# nrf7120E_enga_application register map
Vendor: Nordic Semiconductor; Series: nrf71; File version: 1
CPU: CM33 r0p4, little endian, MPU, FPU, 3 interrupt priority bits, 270 interrupts, 4 SAU regions
Registers are 32-bit, read-write, reset 0x0 unless marked. A register's access mark holds for its fields unless they carry their own. Offsets are from the block's base; [hi:lo] are bit positions; lines under a group give offsets from that group; {n}, {i} and the like mark numbered series; 'fields as' and 'values as' point back to an identical list.

## GLOBAL_USBHSCORE_NS (part 3 of 3) — USBHSCORE 0
Base 0x40020000
Same registers: GLOBAL_USBHSCORE_S 0x50020000
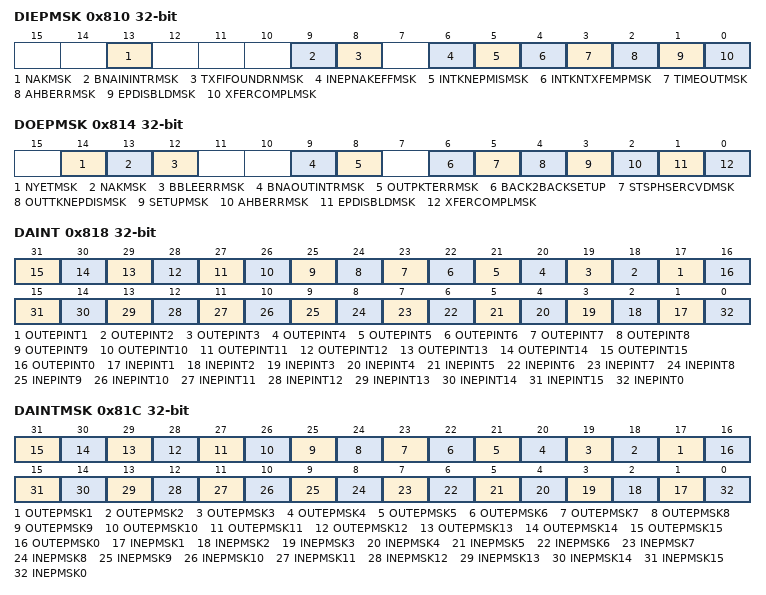
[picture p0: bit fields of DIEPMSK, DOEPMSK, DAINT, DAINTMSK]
0x810 DIEPMSK — Device IN Endpoint Common Interrupt Mask Register
  [13] NAKMSK — NAK interrupt Mask (NAKMsk)
    0=MASK (Mask NAK Interrupt); 1=NOMASK (No Mask NAK Interrupt)
  [9] BNAININTRMSK — BNA interrupt Mask (BNAInIntrMsk)
    0=MASK (Mask BNA Interrupt); 1=NOMASK (No BNA Interrupt Mask)
  [8] TXFIFOUNDRNMSK — Fifo Underrun Mask (TxfifoUndrnMsk)
    0=MASK (Mask Fifo Underrun Interrupt); 1=NOMASK (No Fifo Underrun Interrupt Mask)
  [6] INEPNAKEFFMSK — IN Endpoint NAK Effective Mask (INEPNakEffMsk)
    0=MASK (Mask IN Endpoint NAK Effective Interrupt); 1=NOMASK (No IN Endpoint NAK Effective Interrupt Mask)
  [5] INTKNEPMISMSK — IN Token received with EP Mismatch Mask (INTknEPMisMsk)
    0=MASK (Mask IN Token received with EP Mismatch Interrupt); 1=NOMASK (No Mask IN Token received with EP Mismatch Interrupt)
  [4] INTKNTXFEMPMSK — IN Token Received When TxFIFO Empty Mask (INTknTXFEmpMsk)
    0=MASK (Mask IN Token Received When TxFIFO Empty Interrupt); 1=NOMASK (No IN Token Received When TxFIFO Empty Interrupt)
  [3] TIMEOUTMSK — Timeout Condition Mask (TimeOUTMsk) (Non-isochronous endpoints)
    0=MASK (Mask Timeout Condition Interrupt); 1=NOMASK (No Timeout Condition Interrupt Mask)
  [2] AHBERRMSK — AHB Error Mask (AHBErrMsk)
    0=MASK (Mask AHB Error Interrupt); 1=NOMASK (No AHB Error Interrupt Mask)
  [1] EPDISBLDMSK — Endpoint Disabled Interrupt Mask (EPDisbldMsk)
    0=MASK (Mask Endpoint Disabled Interrupt); 1=NOMASK (No Endpoint Disabled Interrupt Mask)
  [0] XFERCOMPLMSK — Transfer Completed Interrupt Mask (XferComplMsk)
    0=MASK (Mask Transfer Completed Interrupt); 1=NOMASK (No Transfer Completed Interrupt Mask)
0x814 DOEPMSK — Device OUT Endpoint Common Interrupt Mask Register
  [14] NYETMSK — NYET interrupt Mask (NYETMsk)
    0=MASK (Mask NYET Interrupt); 1=NOMASK (No NYET Interrupt Mask)
  [13] NAKMSK — NAK interrupt Mask (NAKMsk)
    0=MASK (Mask NAK Interrupt); 1=NOMASK (No NAK Interrupt Mask)
  [12] BBLEERRMSK — Babble Error interrupt Mask (BbleErrMsk)
    0=MASK (Mask Babble Error Interrupt); 1=NOMASK (No Babble Error Interrupt Mask)
  [9] BNAOUTINTRMSK — BNA interrupt Mask (BnaOutIntrMsk)
    values as DIEPMSK.BNAININTRMSK
  [8] OUTPKTERRMSK — OUT Packet Error Mask (OutPktErrMsk)
    0=MASK (Mask OUT Packet Error Interrupt); 1=NOMASK (No OUT Packet Error Interrupt Mask)
  [6] BACK2BACKSETUP — Back-to-Back SETUP Packets Received Mask (Back2BackSETup)
    0=MASK (Mask Back-to-Back SETUP Packets Received Interrupt); 1=NOMASK (No Back-to-Back SETUP Packets Received Interrupt Mask)
  [5] STSPHSERCVDMSK — Status Phase Received Mask (StsPhseRcvdMsk)
    0=MASK (Status Phase Received Mask); 1=NOMASK (No Status Phase Received Mask)
  [4] OUTTKNEPDISMSK — OUT Token Received when Endpoint Disabled Mask (OUTTknEPdisMsk)
    0=MASK (Mask OUT Token Received when Endpoint Disabled Interrupt); 1=NOMASK (No OUT Token Received when Endpoint Disabled Interrupt Mask)
  [3] SETUPMSK — SETUP Phase Done Mask (SetUPMsk)
    0=MASK (Mask SETUP Phase Done Interrupt); 1=NOMASK (No SETUP Phase Done Interrupt Mask)
  [2] AHBERRMSK — AHB Error (AHBErrMsk)
    values as DIEPMSK.AHBERRMSK
  [1] EPDISBLDMSK — Endpoint Disabled Interrupt Mask (EPDisbldMsk)
    values as DIEPMSK.EPDISBLDMSK
  [0] XFERCOMPLMSK — Transfer Completed Interrupt Mask (XferComplMsk)
    values as DIEPMSK.XFERCOMPLMSK
0x818 DAINT — Device All Endpoints Interrupt Register
  [n+16] OUTEPINT{n} ro (n=1..15) — OUT Endpoint {n} Interrupt Bit
    0=INACTIVE (No Interrupt); 1=ACTIVE (Interrupt is active for the OUT EP)
  [16] OUTEPINT0 ro — OUT Endpoint 0 Interrupt Bit
    0=INACTIVE (No Interrupt); 1=ACTIVE (Interrupt is active for OUT EP0)
  [n] INEPINT{n} ro (n=1..15) — IN Endpoint {n} Interrupt Bit
    0=INACTIVE (No Interrupt); 1=ACTIVE (Interrupt is active for the IN EP)
  [0] INEPINT0 ro — IN Endpoint 0 Interrupt Bit
    0=INACTIVE (No Interrupt); 1=ACTIVE (Interrupt is active for IN EP0)
0x81C DAINTMSK — Device All Endpoints Interrupt Mask Register
  [n+16] OUTEPMSK{n} (n=1..15) — OUT Endpoint {n} Interrupt mask Bit
    0=MASK (Mask OUT Endpoint Interrupt); 1=NOMASK (No Interrupt mask)
  [16] OUTEPMSK0 — OUT Endpoint 0 Interrupt mask Bit
    0=MASK (Mask OUT Endpoint 0 Interrupt); 1=NOMASK (No Interrupt mask)
  [n] INEPMSK{n} (n=1..15) — IN Endpoint {n} Interrupt mask Bit
    0=MASK (Mask IN Endpoint Interrupt); 1=NOMASK (No Interrupt mask)
  [0] INEPMSK0 — IN Endpoint 0 Interrupt mask Bit
    0=MASK (Mask IN Endpoint 0 Interrupt); 1=NOMASK (No Interrupt mask)
0x828 DVBUSDIS reset 0x17D7 — Device VBUS Discharge Time Register
  [15:0] DVBUSDIS — Device VBUS Discharge Time (DVBUSDis)
0x82C DVBUSPULSE reset 0x5B8 — Device VBUS Pulsing Time Register
  [11:0] DVBUSPULSE — Device VBUS Pulsing Time (DVBUSPulse)
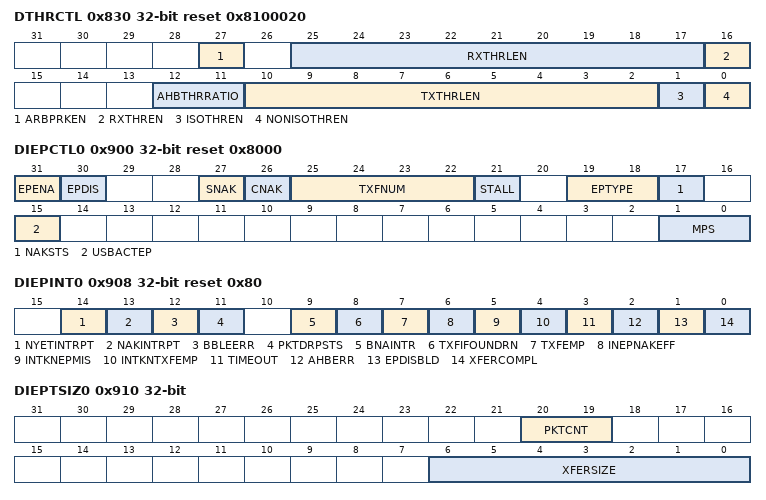
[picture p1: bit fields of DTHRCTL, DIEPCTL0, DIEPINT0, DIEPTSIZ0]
0x830 DTHRCTL reset 0x8100020 — Device Threshold Control Register
  [27] ARBPRKEN — Arbiter Parking Enable (ArbPrkEn)
    0=DISABLED (Disable DMA arbiter parking); 1=ENABLED (Enable DMA arbiter parking for IN endpoints)
  [25:17] RXTHRLEN — Receive Threshold Length (RxThrLen)
  [16] RXTHREN — Receive Threshold Enable (RxThrEn)
    0=DISABLED (Disable thresholding); 1=ENABLED (Enable thresholding in the receive direction)
  [12:11] AHBTHRRATIO — AHB Threshold Ratio (AHBThrRatio)
    0=THRESZERO (AHB threshold = MAC threshold); 1=THRESONE (AHB threshold = MAC threshold /2); 2=THRESTWO (AHB threshold = MAC threshold /4); 3=THRESTHREE (AHB threshold = MAC threshold /8)
  [10:2] TXTHRLEN — Transmit Threshold Length (TxThrLen)
  [1] ISOTHREN
    0=DISABLED (No thresholding); 1=ENABLED (Enables thresholding for isochronous IN endpoints)
  [0] NONISOTHREN — Non-ISO IN Endpoints Threshold Enable. (NonISOThrEn)
    0=DISABLED (No thresholding); 1=ENABLED (Enable thresholding for non-isochronous IN endpoints)
0x834 DIEPEMPMSK — Device IN Endpoint FIFO Empty Interrupt Mask Register
  [15:0] INEPTXFEMPMSK — IN EP Tx FIFO Empty Interrupt Mask Bits (InEpTxfEmpMsk)
    1=EP0_MASK (Mask IN EP0 Tx FIFO Empty Interrupt); 2=EP1_MASK (Mask IN EP1 Tx FIFO Empty Interrupt); 4=EP2_MASK (Mask IN EP2 Tx FIFO Empty Interrupt); 8=EP3_MASK (Mask IN EP3 Tx FIFO Empty Interrupt); 16=EP4_MASK (Mask IN EP4 Tx FIFO Empty Interrupt); 32=EP5_MASK (Mask IN EP5 Tx FIFO Empty Interrupt); 64=EP6_MASK (Mask IN EP6 Tx FIFO Empty Interrupt); 128=EP7_MASK (Mask IN EP7 Tx FIFO Empty Interrupt); 0x100=EP8_MASK (Mask IN EP8 Tx FIFO Empty Interrupt); 0x200=EP9_MASK (Mask IN EP9 Tx FIFO Empty Interrupt); 0x400=EP10_MASK (Mask IN EP10 Tx FIFO Empty Interrupt); 0x800=EP11_MASK (Mask IN EP11 Tx FIFO Empty Interrupt); 0x1000=EP12_MASK (Mask IN EP12 Tx FIFO Empty Interrupt); 0x2000=EP13_MASK (Mask IN EP13 Tx FIFO Empty Interrupt); 0x4000=EP14_MASK (Mask IN EP14 Tx FIFO Empty Interrupt); 0x8000=EP15_MASK (Mask IN EP15 Tx FIFO Empty Interrupt)
0x900 DIEPCTL0 reset 0x8000 — Device Control IN Endpoint 0 Control Register
  [31] EPENA — Endpoint Enable (EPEna)
    0=INACTIVE (No action); 1=ACTIVE (Enable Endpoint)
  [30] EPDIS — Endpoint Disable (EPDis)
    0=INACTIVE (No action); 1=ACTIVE (Disabled Endpoint)
  [27] SNAK wo
    0=NOSET (No action); 1=SET (Set NAK)
  [26] CNAK wo
    0=NOCLEAR (No action); 1=CLEAR (Clear NAK)
  [25:22] TXFNUM — TxFIFO Number (TxFNum)
    {v}=TXFIFO{v} (v=0..15)
  [21] STALL — STALL Handshake (Stall)
    0=INACTIVE (No Stall); 1=ACTIVE (Stall Handshake)
  [19:18] EPTYPE ro — Endpoint Type (EPType)
    0=ACTIVE (Endpoint Control 0)
  [17] NAKSTS ro — NAK Status (NAKSts)
    0=INACTIVE (The core is transmitting non-NAK handshakes based on the FIFO status); 1=ACTIVE (The core is transmitting NAK handshakes on this endpoint)
  [15] USBACTEP ro — USB Active Endpoint (USBActEP)
    1=ACTIVE0 (Control endpoint is always active)
  [1:0] MPS — Maximum Packet Size (MPS)
    0=BYTES64 (64 bytes); 1=BYTES32 (32 bytes); 2=BYTES16 (16 bytes); 3=BYTES8 (8 bytes)
0x908 DIEPINT0 reset 0x80 — Device IN Endpoint 0 Interrupt Register
  [14] NYETINTRPT — NYET Interrupt (NYETIntrpt)
    0=INACTIVE (No interrupt); 1=ACTIVE (NYET Interrupt)
  [13] NAKINTRPT — NAK Interrupt (NAKInterrupt)
    0=INACTIVE (No interrupt); 1=ACTIVE (NAK Interrupt)
  [12] BBLEERR — NAK Interrupt (BbleErr)
    0=INACTIVE (No interrupt); 1=ACTIVE (BbleErr interrupt)
  [11] PKTDRPSTS — Packet Drop Status (PktDrpSts)
    0=INACTIVE (No interrupt); 1=ACTIVE (Packet Drop Status)
  [9] BNAINTR — BNA (Buffer Not Available) Interrupt (BNAIntr)
    0=INACTIVE (No BNA interrupt); 1=ACTIVE (BNA interrupt)
  [8] TXFIFOUNDRN — Fifo Underrun (TxfifoUndrn)
    0=INACTIVE (No Fifo Underrun interrupt); 1=ACTIVE (Fifo Underrun interrupt)
  [7] TXFEMP ro — Transmit FIFO Empty (TxFEmp)
    0=INACTIVE (No Transmit FIFO Empty interrupt); 1=ACTIVE (Transmit FIFO Empty interrupt)
  [6] INEPNAKEFF — IN Endpoint NAK Effective (INEPNakEff)
    0=INACTIVE (No IN Endpoint NAK Effective interrupt); 1=ACTIVE (IN Endpoint NAK Effective interrupt)
  [5] INTKNEPMIS — IN Token Received with EP Mismatch (INTknEPMis)
    0=INACTIVE (No IN Token Received with EP Mismatch interrupt); 1=ACTIVE (IN Token Received with EP Mismatch interrupt)
  [4] INTKNTXFEMP — IN Token Received When TxFIFO is Empty (INTknTXFEmp)
    0=INACTIVE (No IN Token Received when TxFIFO Empty interrupt); 1=ACTIVE (IN Token Received when TxFIFO Empty Interrupt)
  [3] TIMEOUT — Timeout Condition (TimeOUT)
    0=INACTIVE (No Timeout interrupt); 1=ACTIVE (Timeout interrupt)
  [2] AHBERR — AHB Error (AHBErr)
    0=INACTIVE (No AHB Error Interrupt); 1=ACTIVE (AHB Error interrupt)
  [1] EPDISBLD — Endpoint Disabled Interrupt (EPDisbld)
    0=INACTIVE (No Endpoint Disabled Interrupt); 1=ACTIVE (Endpoint Disabled Interrupt)
  [0] XFERCOMPL — Transfer Completed Interrupt (XferCompl)
    0=INACTIVE (No Transfer Complete Interrupt); 1=ACTIVE (Transfer Completed Interrupt)
0x910 DIEPTSIZ0 — Device IN Endpoint 0 Transfer Size Register
  [20:19] PKTCNT — Packet Count (PktCnt)
  [6:0] XFERSIZE — Transfer Size (XferSize)
0x914 DIEPDMA0 — Device IN Endpoint 0 DMA Address Register
  [31:0] DMAADDR
{0x918+0x20*i} DTXFSTS{i} reset 0xC00 (i=0..15) — Device IN Endpoint Transmit FIFO Status Register {i}
  [15:0] INEPTXFSPCAVAIL ro — IN Endpoint TxFIFO Space Avail (INEPTxFSpcAvail)
0x91C DIEPDMAB0 — Device IN Endpoint 0 Buffer Address Register
  [31:0] DMABUFFERADDR ro — Holds the current buffer address.This register is updated as and when the data
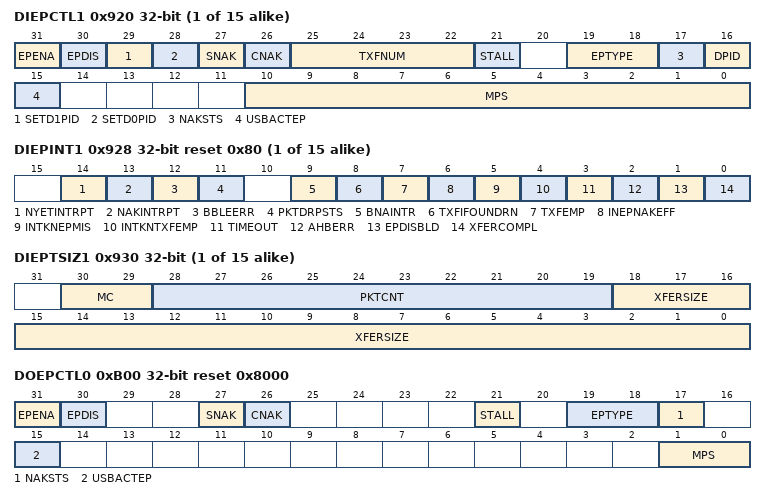
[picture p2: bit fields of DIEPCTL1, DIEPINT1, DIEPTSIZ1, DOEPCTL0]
{0x900+0x20*i} DIEPCTL{i} (i=1..15) — Device Control IN Endpoint Control Register {i}
  [31] EPENA — Endpoint Enable (EPEna)
    0=INACTIVE (No Action); 1=ACTIVE (Enable Endpoint)
  [30] EPDIS — Endpoint Disable (EPDis)
    0=INACTIVE (No Action); 1=ACTIVE (Disable Endpoint)
  [29] SETD1PID wo — Set DATA1 PID (SetD1PID)
    0=DISABLED (Disables Set DATA1 PID or Do not force Odd (micro)Frame); 1=ENABLED (Set Endpoint Data PID to DATA1 or Sets EO_FrNum field to Odd (micro)Frame)
  [28] SETD0PID wo — Set DATA0 PID (SetD0PID)
    0=DISABLED (Disables Set DATA0 PID or Do not force Even (micro)Frame); 1=ENABLED (Set Endpoint Data PID to DATA0 or Sets EO_FrNum field to Even (micro)Frame)
  [27] SNAK wo — Set NAK (SNAK)
    0=INACTIVE (No Set NAK); 1=ACTIVE (Set NAK)
  [26] CNAK wo — Clear NAK (CNAK)
    0=INACTIVE (No Clear NAK); 1=ACTIVE (Clear NAK)
  [25:22] TXFNUM — TxFIFO Number (TxFNum)
    {v}=TXFIFO{v} (v=0..15)
  [21] STALL — STALL Handshake (Stall)
    0=INACTIVE (STALL All non-active tokens); 1=ACTIVE (STALL All Active Tokens)
  [19:18] EPTYPE — Endpoint Type (EPType)
    0=CONTROL; 1=ISOCHRONOUS; 2=BULK; 3=INTERRUP (Interrupt)
  [17] NAKSTS ro — NAK Status (NAKSts)
    0=NONNAK (The core is transmitting non-NAK handshakes based on the FIFO status); 1=NAK (The core is transmitting NAK handshakes on this endpoint)
  [16] DPID ro
    0=DATA0EVENFRM (DATA0 or Even Frame); 1=DATA1ODDFRM (DATA1 or Odd Frame)
  [15] USBACTEP — USB Active Endpoint (USBActEP)
    0=DISABLED (Not Active); 1=ENABLED (USB Active Endpoint)
  [10:0] MPS — Maximum Packet Size (MPS)
{0x908+0x20*i} DIEPINT{i} reset 0x80 (i=1..15) — Device IN Endpoint Interrupt Register {i}
  [14] NYETINTRPT — NYET Interrupt (NYETIntrpt)
    0=INACTIVE (No NYET interrupt); 1=ACTIVE (NYET Interrupt)
  [13] NAKINTRPT — NAK Interrupt (NAKInterrupt)
    0=INACTIVE (No NAK interrupt); 1=ACTIVE (NAK Interrupt)
  [12] BBLEERR — NAK Interrupt (BbleErr)
    0=INACTIVE (No interrupt); 1=ACTIVE (BbleErr interrupt)
  [11] PKTDRPSTS — Packet Drop Status (PktDrpSts)
    0=INACTIVE (No interrupt); 1=ACTIVE (Packet Drop Status interrupt)
  [9] BNAINTR — BNA (Buffer Not Available) Interrupt (BNAIntr)
    0=INACTIVE (No BNA interrupt); 1=ACTIVE (BNA interrupt)
  [8] TXFIFOUNDRN — Fifo Underrun (TxfifoUndrn)
    0=INACTIVE (No Tx FIFO Underrun interrupt); 1=ACTIVE (TxFIFO Underrun interrupt)
  [7] TXFEMP ro — Transmit FIFO Empty (TxFEmp)
    values as DIEPINT0.TXFEMP
  [6] INEPNAKEFF — IN Endpoint NAK Effective (INEPNakEff)
    0=INACTIVE (No Endpoint NAK Effective interrupt); 1=ACTIVE (IN Endpoint NAK Effective interrupt)
  [5] INTKNEPMIS — IN Token Received with EP Mismatch (INTknEPMis)
    values as DIEPINT0.INTKNEPMIS
  [4] INTKNTXFEMP — IN Token Received When TxFIFO is Empty (INTknTXFEmp)
    0=INACTIVE (No IN Token Received interrupt); 1=ACTIVE (IN Token Received Interrupt)
  [3] TIMEOUT — Timeout Condition (TimeOUT)
    values as DIEPINT0.TIMEOUT
  [2] AHBERR — AHB Error (AHBErr)
    values as DIEPINT0.AHBERR
  [1] EPDISBLD — Endpoint Disabled Interrupt (EPDisbld)
    values as DIEPINT0.EPDISBLD
  [0] XFERCOMPL — Transfer Completed Interrupt (XferCompl)
    0=INACTIVE (No Transfer Complete Interrupt); 1=ACTIVE (Transfer Complete Interrupt)
{0x910+0x20*i} DIEPTSIZ{i} (i=1..15) — Device IN Endpoint Transfer Size Register {i}
  [30:29] MC
    1=PACKETONE (1 packet); 2=PACKETTWO (2 packets); 3=PACKETTHREE (3 packets)
  [28:19] PKTCNT — Packet Count (PktCnt)
  [18:0] XFERSIZE — Transfer Size (XferSize)
{0x914+0x20*i} DIEPDMA{i} (i=1..15) — Device IN Endpoint DMA Address Register {i}
  [31:0] DMAADDR — Holds the start address of the external memory for storing or fetching endpoint
{0x91C+0x20*i} DIEPDMAB{i} (i=1..15) — Device IN Endpoint Buffer Address Register {i}
  fields as DIEPDMAB0
0xB00 DOEPCTL0 reset 0x8000 — Device Control OUT Endpoint 0 Control Register
  [31] EPENA — Endpoint Enable (EPEna)
    0=INACTIVE (No action); 1=ACTIVE (Enable Endpoint)
  [30] EPDIS ro — Endpoint Disable (EPDis)
    0=INACTIVE (No Endpoint disable)
  [27] SNAK wo — Set NAK (SNAK)
    0=NOSET (No action); 1=SET (Set NAK)
  [26] CNAK wo — Clear NAK (CNAK)
    0=NOCLEAR (No action); 1=CLEAR (Clear NAK)
  [21] STALL — STALL Handshake (Stall)
    0=INACTIVE (No Stall); 1=ACTIVE (Stall Handshake)
  [19:18] EPTYPE ro — Endpoint Type (EPType)
    0=ACTIVE (Endpoint Control 0)
  [17] NAKSTS ro — NAK Status (NAKSts)
    values as DIEPCTL0.NAKSTS
  [15] USBACTEP ro — USB Active Endpoint (USBActEP)
    1=ACTIVE (USB Active Endpoint 0)
  [1:0] MPS ro — Maximum Packet Size (MPS)
    0=BYTE64 (64 bytes); 1=BYTE32 (32 bytes); 2=BYTE16 (16 bytes); 3=BYTE8 (8 bytes)
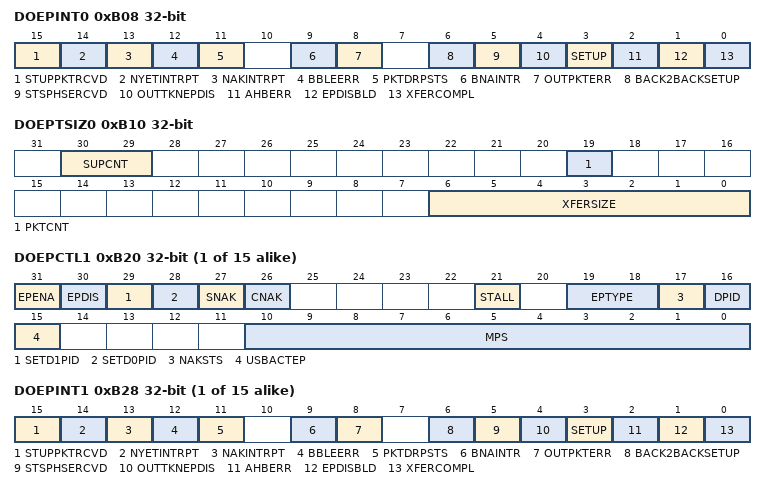
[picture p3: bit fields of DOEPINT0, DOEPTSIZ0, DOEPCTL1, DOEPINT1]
0xB08 DOEPINT0 — Device OUT Endpoint 0 Interrupt Register
  [15] STUPPKTRCVD — Setup Packet Received
    0=NOT_RCVD (No Setup packet received); 1=RCVD (Setup packet received)
  [14] NYETINTRPT — NYET Interrupt (NYETIntrpt)
    0=INACTIVE (No NYET interrupt); 1=ACTIVE (NYET Interrupt)
  [13] NAKINTRPT — NAK Interrupt (NAKInterrupt)
    0=INACTIVE (No NAK interrupt); 1=ACTIVE (NAK Interrupt)
  [12] BBLEERR — NAK Interrupt (BbleErr)
    0=INACTIVE (No BbleErr interrupt); 1=ACTIVE (BbleErr interrupt)
  [11] PKTDRPSTS — Packet Drop Status (PktDrpSts)
    values as DIEPINT1.PKTDRPSTS
  [9] BNAINTR — BNA (Buffer Not Available) Interrupt (BNAIntr)
    0=INACTIVE (No BNA interrupt); 1=ACTIVE (BNA interrupt)
  [8] OUTPKTERR — OUT Packet Error (OutPktErr)
    0=INACTIVE (No OUT Packet Error); 1=ACTIVE (OUT Packet Error)
  [6] BACK2BACKSETUP — Back-to-Back SETUP Packets Received (Back2BackSETup)
    0=INACTIVE (No Back-to-Back SETUP Packets Received); 1=ACTIVE (Back-to-Back SETUP Packets Received)
  [5] STSPHSERCVD — Status Phase Received for Control Write (StsPhseRcvd)
    0=INACTIVE (No Status Phase Received for Control Write); 1=ACTIVE (Status Phase Received for Control Write)
  [4] OUTTKNEPDIS — OUT Token Received When Endpoint Disabled (OUTTknEPdis)
    0=INACTIVE (No OUT Token Received When Endpoint Disabled); 1=ACTIVE (OUT Token Received When Endpoint Disabled)
  [3] SETUP — SETUP Phase Done (SetUp)
    0=INACTIVE (No SETUP Phase Done); 1=ACTIVE (SETUP Phase Done)
  [2] AHBERR — AHB Error (AHBErr)
    values as DIEPINT0.AHBERR
  [1] EPDISBLD — Endpoint Disabled Interrupt (EPDisbld)
    values as DIEPINT0.EPDISBLD
  [0] XFERCOMPL — Transfer Completed Interrupt (XferCompl)
    values as DIEPINT1.XFERCOMPL
0xB10 DOEPTSIZ0 — Device OUT Endpoint 0 Transfer Size Register
  [30:29] SUPCNT — SETUP Packet Count (SUPCnt)
    1=ONEPACKET (1 packet); 2=TWOPACKET (2 packets); 3=THREEPACKET (3 packets)
  [19] PKTCNT — Packet Count (PktCnt)
  [6:0] XFERSIZE — Transfer Size (XferSize)
0xB14 DOEPDMA0 — Device OUT Endpoint 0 DMA Address Register
  fields as DIEPDMA1
0xB1C DOEPDMAB0 — Device OUT Endpoint 0 DMA Buffer Address Register
  [31:0] DMABUFFERADDR ro
{0xB00+0x20*i} DOEPCTL{i} (i=1..15) — Device Control OUT Endpoint Control Register {i}
  [31] EPENA — Endpoint Enable (EPEna)
    0=INACTIVE (No Action); 1=ACTIVE (Enable Endpoint)
  [30] EPDIS — Endpoint Disable (EPDis)
    0=INACTIVE (No Action); 1=ACTIVE (Disable Endpoint)
  [29] SETD1PID wo — Set DATA1 PID (SetD1PID)
    0=DISABLED (Disables Set DATA1 PID or Do not force Odd Frame); 1=ENABLED (Set Endpoint Data PID to DATA1 or Sets EO_FrNum field to odd (micro)Frame)
  [28] SETD0PID wo — Set DATA0 PID (SetD0PID)
    0=DISABLED (Disables Set DATA0 PID or Do not force Even Frame); 1=ENABLED (Set Endpoint Data PID to DATA0 or Sets EO_FrNum field to odd (micro)Frame)
  [27] SNAK wo — Set NAK (SNAK)
    0=INACTIVE (No Set NAK); 1=ACTIVE (Set NAK)
  [26] CNAK wo
    0=INACTIVE (No Clear NAK); 1=ACTIVE (Clear NAK)
  [21] STALL — STALL Handshake (Stall)
    values as DIEPCTL1.STALL
  [19:18] EPTYPE — Endpoint Type (EPType)
    0=CONTROL; 1=ISOCHRONOUS; 2=BULK; 3=INTERRUPT
  [17] NAKSTS ro — NAK Status (NAKSts)
    values as DIEPCTL1.NAKSTS
  [16] DPID ro — Endpoint Data PID (DPID)
    0=INACTIVE (Endpoint Data PID not active); 1=ACTIVE (Endpoint Data PID active)
  [15] USBACTEP — USB Active Endpoint (USBActEP)
    0=DISABLED (Not Active); 1=ENABLED (USB Active Endpoint)
  [10:0] MPS — Maximum Packet Size (MPS)
{0xB08+0x20*i} DOEPINT{i} (i=1..15) — Device OUT Endpoint Interrupt Register {i}
  fields as DOEPINT0
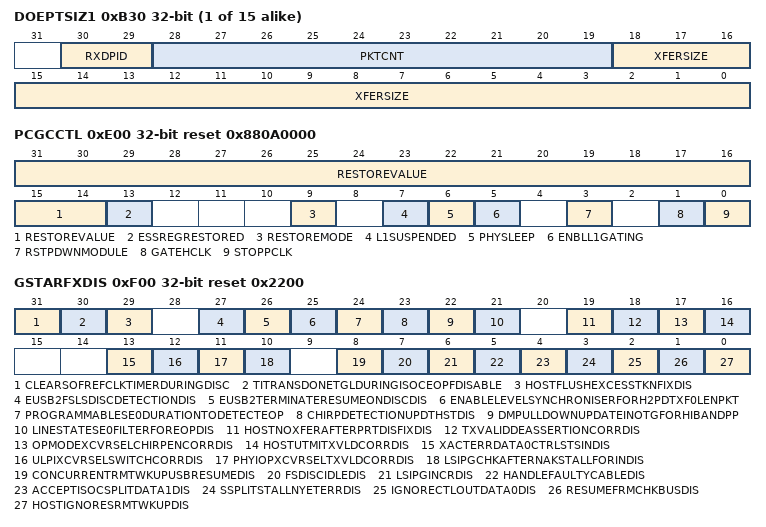
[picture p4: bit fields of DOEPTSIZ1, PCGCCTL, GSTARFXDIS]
{0xB10+0x20*i} DOEPTSIZ{i} (i=1..15) — Device OUT Endpoint Transfer Size Register {i}
  [30:29] RXDPID ro
    0=DATA0; 1=DATA2PACKET1 (DATA2 or 1 packet); 2=DATA1PACKET2 (DATA1 or 2 packets); 3=MDATAPACKET3 (MDATA or 3 packets)
  [28:19] PKTCNT — Packet Count (PktCnt)
  [18:0] XFERSIZE — Transfer Size (XferSize)
{0xB14+0x20*i} DOEPDMA{i} (i=1..15) — Device OUT Endpoint DMA Address Register {i}
  fields as DIEPDMA1
{0xB1C+0x20*i} DOEPDMAB{i} (i=1..15) — Device OUT Endpoint Buffer Address Register {i}
  fields as DIEPDMAB0
0xE00 PCGCCTL reset 0x880A0000 — Power and Clock Gating Control Register
  [31:14] RESTOREVALUE — Restore Value (RestoreValue)
  [13] ESSREGRESTORED wo — Essential Register Values Restored (EssRegRestored)
    0=NOT_RESTORED (Register values of essential registers are not restored); 1=RESTORED (Register values of essential registers have been restored)
  [9] RESTOREMODE — Restore Mode (RestoreMode)
    0=DISABLED (In Host mode,this bit indicates Host-initiated Resume and Reset. In Device mode, this bit indicates Device-initiated Remote Wakeup); 1=ENABLED (In Host mode,this bit indicates Device-initiated Remote Wakeup. In Device mode, this bit indicates Host-initiated Resume and Reset)
  [7] L1SUSPENDED ro — L1 Deep Sleep
    0=INACTIVE (Non Deep Sleep); 1=ACTIVE (Deep Sleep)
  [6] PHYSLEEP ro — PHY In Sleep
    0=INACTIVE (Phy not in Sleep state); 1=ACTIVE (Phy in Sleep state)
  [5] ENBLL1GATING — Enable Sleep Clock Gating
    0=DISABLED (The PHY clock is not gated in Sleep state); 1=ENABLED (The Core internal clock gating is enabled in Sleep state)
  [3] RSTPDWNMODULE — Reset Power-Down Modules (RstPdwnModule)
    0=ON (Power is turned on); 1=OFF (Power is turned off)
  [1] GATEHCLK — Gate Hclk (GateHclk)
    0=DISABLED (Clears this bit when the USB is resumed or a new session starts); 1=ENABLED (Sets this bit to gate hclk to modules when the USB is suspended or the session is not valid)
  [0] STOPPCLK — Stop Pclk (StopPclk)
    0=DISABLED (Disable Stop Pclk); 1=ENABLED (Enable Stop Pclk)
0xF00 GSTARFXDIS reset 0x2200 — Global STAR Fix Disable Register
  [31] CLEARSOFREFCLKTIMERDURINGDISC — Disable the STAR fix added to clear the SOF refclk timer during disconnect detection. The STAR fix is added when using both UTMI and eUSB2 PHY.
    0=ENABLE_FIX (SOF refclk timer is cleared immediately after device disconnect is detected.); 1=DISABLE_FIX (SOF refclk timer is not cleared immediately after device disconnect is detected.)
  [30] TITRANSDONETGLDURINGISOCEOPFDISABLE — Disable the fix added to not toggle ti_trans_done in SEND_EOP state when the ISOC in tokens responds with zero length packets after end of periodic frame till next start of frame. The fix is added when operating in descriptor dma device mode.
    0=ENABLE_FIX (ti_transdone is not toggled after eopf during ISOC IN transfer till next SOF); 1=DISABLE_FIX (ti_transdone is toggled after eopf during ISOC IN transfer till next SOF)
  [29] HOSTFLUSHEXCESSTKNFIXDIS — Disable fix for recovering the Host controller when sufficient time is not available in the current uF for an overscheduled ISOC OUT or INTR IN transfer.
    0=ENABLE_FIX (Host controller functionality is as expected if there is an overscheduled ISOC OUT or INTR IN transfer); 1=DISABLE_FIX (Host controller functionality cannot be determined if there is an overscheduled ISOC OUT or INTR IN transfer)
  [27] EUSB2FSLSDISCDETECTIONDIS — Disable fix for FS/LS disconnect detection using UTMI HostDisconnect in MAC PRT.
    0=ENABLE_FIX (Host controller detects FS/LS disconnect using utmi_hostdisconnect signal); 1=DISABLE_FIX (Host controller detects disconnect by monitoring 2.5us of SE0 on DP/DM)
  [26] EUSB2TERMINATERESUMEONDISCDIS — Disable fix for Terminating Resume if UTMI HostDisconnect is detected.
    0=ENABLE_FIX (Host controller terminates Resume if HostDisconnect is asserted); 1=DISABLE_FIX (Host controller does not terminate Resume if HostDisconnect is asserted)
  [25] ENABLELEVELSYNCHRONISERFORH2PDTXF0LENPKT — Disable the STAR fix added for h2pd_txf_0len_pkt signal which is passing through a level synchronizer.
    0=ENABLE_FIX (level synchroniser for h2pd_txf_0len_pkt is enabled and disabled dummy synchronizer); 1=DISABLE_FIX (level synchroniser for h2pd_txf_0len_pkt is disabled and connected through dummy synchronizer)
  [24] PROGRAMMABLESE0DURATIONTODETECTEOP — Disable the STAR fix added for programmable se0 duration to detect EOP in Host mode .
    0=ENABLE_FIX (Programmable se0 duration to detect EOP in Host mode is enabled); 1=DISABLE_FIX (Programmable se0 duration to detect EOP in Host mode is disabled)
  [23] CHIRPDETECTIONUPDTHSTDIS — Disable the Chirp detection logic change in host mode.
    0=ENABLE_FIX (Chirp detection logic in MAC PRT module depends on the delayed WAIT_CHIRP state and only valid chirp K from device is detected); 1=DISABLE_FIX (Chirp detection logic depends on the WAIT_CHIRP state and controller might detect false chirp K from device)
  [22] DMPULLDOWNUPDATEINOTGFORHIBANDPP — Disable the STAR fix added for utmiotg_dmpulldown update in Hibernation and Partial power down modes.
    0=ENABLE_FIX (utmiotg_dmpulldown logic for hiberabtion and partial power down is enabled); 1=DISABLE_FIX (utmiotg_dmpulldown logic for hiberabtion and partial power down is not enabled)
  [21] LINESTATESE0FILTERFOREOPDIS — Disable the STAR fix added for filtering SE0 from the linestate during EOP detection..
    0=ENABLE_FIX (Filter for linestate is enabled); 1=DISABLE_FIX (Filter for linestate is not enabled)
  [19] HOSTNOXFERAFTERPRTDISFIXDIS — Disable the STAR fix added for correcting Host behavior when port is disabled.
    0=ENABLE_FIX (Txvalid is not asserted when port is disabled); 1=DISABLE_FIX (Txvalid can be asserted when port is disabled)
  [18] TXVALIDDEASSERTIONCORRDIS — Disable the STAR fix added for correcting Txvalid deassertion on UTMI Interface when soft disconnect is done.
    0=ENABLE_FIX (Txvalid is deasserted during soft disconnect after receiving Txready from the PHY); 1=DISABLE_FIX (Txvalid is deasserted during soft disconnect without waiting for Txready from the PHY)
  [17] OPMODEXCVRSELCHIRPENCORRDIS — Disable the STAR fix added for correcting Opmode and XcvrSel on UTMI Interface when reset is detected in suspend state.
    0=ENABLE_FIX (Valid Combination of Opmode and XcvrSel is driven when reset is detected in suspend state); 1=DISABLE_FIX (Invalid Combination of Opmode and XcvrSel is driven when reset is detected in suspend state)
  [16] HOSTUTMITXVLDCORRDIS — Disable the correction to OpMode/XcvrSel/TermSel on UTMI Interface in Host mode.
    0=ENABLE_FIX (Opmode, XcvrSel, TermSel are changed by the Host Controller after TxValid goes LOW (1'b0)); 1=DISABLE_FIX (Opmode, XcvrSel, TermSel are changed by the Host Controller without waiting for TxValid to go LOW (1'b0) during SOF transmission)
  [13] XACTERRDATA0CTRLSTSINDIS — Disable the STAR fix added for Host controller to report transaction error when DATA0 PID is received for CTRL STATUS IN transfer in DMA mode
    0=ENABLE_FIX (Host controller reports transaction error when DATA0 PID is received for CTRL STATUS IN transfer in DMA mode); 1=DISABLE_FIX (Host controller retries the transfer when DATA0 PID is received for CTRL STATUS IN transfer in DMA mode)
  [12] ULPIXCVRSELSWITCHCORRDIS — Disable the STAR fix added for Host controller to increase the preamble transceiver select switch delay to accommodate time taken for ULPI function control write
    0=ENABLE_FIX (Host controller waits for previous functional register update to complete before switching the transceiver select again or asserting txvalid); 1=DISABLE_FIX (Host controller does not wait for the previous functional register update to complete before switching the transceiver select again or asserting txvalid)
  [11] PHYIOPXCVRSELTXVLDCORRDIS — Disable the STAR fix added for Host controller to increase the gap between utmi_xcvrselect switching and utmi_txvalid assertion in LS/FS mode
    0=ENABLE_FIX (Host controller asserts utmi_txvalid at least 2 utmi_clk cycles after utmi_xcvrselect switching); 1=DISABLE_FIX (Host controller can assert utmi_txvalid after 1 utmi_clk cycle of utmi_xcvrselect switching)
  [10] LSIPGCHKAFTERNAKSTALLFORINDIS — Disable the STAR fix added for Host controller to wait for IPG duration to send next token after receiving NAK/STALL for previous IN token with FS/LS device
    0=ENABLE_FIX (Host controller checks IPG after NAK/STALL for IN token); 1=DISABLE_FIX (Host controller does not check IPG after NAK/STALL for IN token)
  [8] CONCURRENTRMTWKUPUSBRESUMEDIS — Disable the STAR fix added for Device controller to not start Remote Wakeup signalling when USB resume has already started
    0=ENABLE_FIX (Device controller does not start remote wakeup signalling when host resume has already started); 1=DISABLE_FIX (Device controller is allowed to start remote wakeup signalling when host resume has already started)
  [7] FSDISCIDLEDIS — Disable the STAR fix added for Device controller to transition to IDLE state during FS device disconnect
    0=ENABLE_FIX (Device controller transitions to IDLE state during FS device disconnect); 1=DISABLE_FIX (Device controller does not transition to IDLE state during FS device disconnect)
  [6] LSIPGINCRDIS — Disable the STAR fix added for Host controller LS mode IPG increment from 2 LS bit times to 3 LS bit times
    0=ENABLE_FIX (Host LS mode IPG is 3 LS bit times); 1=DISABLE_FIX (Host LS mode IPG is 2 LS bit times)
  [5] HANDLEFAULTYCABLEDIS — Disable the STAR fix added for Host controller to handle Faulty cable scenarios
    0=ENABLE_FIX (Fix for handling faulty cable enabled); 1=DISABLE_FIX (Fix for handling faulty cable disabled)
  [4] ACCEPTISOCSPLITDATA1DIS — Disable the STAR fix added for Host controller to accept DATA1 PID from device for ISOC Split transfers
    0=ENABLE_FIX (Transaction Error not reported when device sends DATA1 PID for ISOC Split); 1=DISABLE_FIX (Transaction Error reported when device sends DATA1 PID for ISOC Split)
  [3] SSPLITSTALLNYETERRDIS — Disable the STAR fix added for Host controller to flag error for SSPLIT STALL/NYET
    0=ENABLE_FIX (Transaction Error reported when device sends STALL/NYET for SSPLIT); 1=DISABLE_FIX (Transaction Error not reported when device sends STALL/NYET for SSPLIT)
  [2] IGNORECTLOUTDATA0DIS — Disable the STAR fix added for Device controller to reject DATA0 for the first Control OUT Data Phase and Control Status OUT Phase
    0=ENABLE_FIX (Transaction Error reported when host sends DATA0 PID); 1=DISABLE_FIX (Transaction Error not reported when host sends DATA0 PID)
  [1] RESUMEFRMCHKBUSDIS — Disable the STAR fix added for Device controller to detect lineK and move to RESUMING state after the 50us pull-up delay ends
    0=ENABLE_FIX (Device controller detects line K and resumes); 1=DISABLE_FIX (Device controller does not detect line K and resume)
  [0] HOSTIGNORESRMTWKUPDIS — Disable the STAR fix added for Device controller to go back to low power mode when Host ignores Remote wakeup
    0=ENABLE_FIX (Device controller goes back into SUSPENDED state when host ignores Remote Wakeup); 1=DISABLE_FIX (Device controller waits indefinitely without entering SUSPENDED state when host ignores the Remote Wakeup)
{0x1000+0x1000*i} DWCOTGDFIFO[{i}] (i=0..15) group — Unspecified
  {0x0+4j} DATA[{j}] (j=0..1023) — Description collection: Data FIFO Access Register Map 0
0x11000 DWCOTGDFIFODIRECTACCESS group — Unspecified
  {0x0+4j} DATA[{j}] (j=0..32767) — Description collection: Data FIFO Direct Access Register Map
